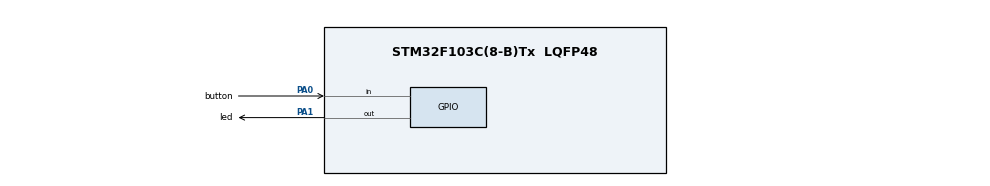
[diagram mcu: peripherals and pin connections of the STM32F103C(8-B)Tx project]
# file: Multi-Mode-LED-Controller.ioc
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Mcu.Family=STM32F1
Mcu.Name=STM32F103C(8-B)Tx
Mcu.Package=LQFP48
NVIC.PriorityGroup=NVIC_PRIORITYGROUP_4
PA0-WKUP.GPIO_Label=button
PA0-WKUP.GPIO_PuPd=GPIO_PULLUP
PA0-WKUP.Signal=GPIO_Input
PA1.GPIO_Label=led
PA1.Signal=GPIO_Output
ProjectManager.HeapSize=0x200
ProjectManager.StackSize=0x400
ProjectManager.TargetToolchain=STM32CubeIDE
RCC.APB1Freq_Value=8000000
RCC.APB2Freq_Value=8000000
board=custom

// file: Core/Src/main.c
/* USER CODE BEGIN Header */
/**
  ******************************************************************************
  * @file           : main.c
  * @brief          : Main program body
  ******************************************************************************
  * @attention
  *
  * Copyright (c) 2026 STMicroelectronics.
  * All rights reserved.
  *
  * This software is licensed under terms that can be found in the LICENSE file
  * in the root directory of this software component.
  * If no LICENSE file comes with this software, it is provided AS-IS.
  *
  ******************************************************************************
  */
/* USER CODE END Header */
#include "main.h"

void SystemClock_Config(void);
static void MX_GPIO_Init(void);

int main(void)
{

  /* MCU Configuration--------------------------------------------------------*/

  /* Reset of all peripherals, Initializes the Flash interface and the Systick. */
  HAL_Init();

  /* Configure the system clock */
  SystemClock_Config();

  /* Initialize all configured peripherals */
  MX_GPIO_Init();

  /* Infinite loop */
  /* USER CODE BEGIN WHILE */

  typedef enum
  {
      MODE_OFF,
      MODE_ON,
      MODE_BLINK_500MS,
      MODE_BLINK_100MS

  } LED_Mode;

  LED_Mode mode = MODE_OFF;

  uint32_t current_time;
  uint32_t previous_time = 0;
  uint32_t debounce_time = 0;

  uint8_t current_button = 0;
  uint8_t previous_button = 0;
  uint8_t led_state = 0;

  while (1)
  {
	  current_time = HAL_GetTick();
	  current_button = HAL_GPIO_ReadPin(GPIOA, GPIO_PIN_0);

	  if ((current_time - debounce_time) >= 30)
	  {
	      debounce_time = current_time;

	      if (current_button == GPIO_PIN_SET && previous_button == GPIO_PIN_RESET)
	      {
	          mode = (mode + 1) % 4;

	          previous_time = current_time;
	          led_state = 0;

	          if (mode == MODE_ON || mode == MODE_BLINK_500MS || mode == MODE_BLINK_100MS)
	          {
	              if (mode == MODE_ON)
	                  led_state = 1;
	              else
	                  led_state = 1;
	          }

	          HAL_GPIO_WritePin(GPIOA, GPIO_PIN_5, led_state ? GPIO_PIN_SET : GPIO_PIN_RESET);
	      }

	      previous_button = current_button;
	  }

	  switch(mode)
	  {
	  case MODE_OFF:
		  HAL_GPIO_WritePin(GPIOA, GPIO_PIN_1, GPIO_PIN_RESET);
		  break;

	  case MODE_ON:
		  HAL_GPIO_WritePin(GPIOA, GPIO_PIN_1, GPIO_PIN_SET);
		  break;

	  case MODE_BLINK_500MS:
		  if((current_time - previous_time) >= 500)
		  {
			  previous_time = current_time;
			  HAL_GPIO_TogglePin(GPIOA, GPIO_PIN_1);
		  }
		  break;

	  case MODE_BLINK_100MS:
		  if((current_time - previous_time) >= 100)
		  {
			  previous_time = current_time;
			  HAL_GPIO_TogglePin(GPIOA, GPIO_PIN_1);
		  }
		  break;

	  default:
		  break;
	  }
	  /* USER CODE END WHILE */

  }
}

void SystemClock_Config(void)
{
  RCC_OscInitTypeDef RCC_OscInitStruct = {0};
  RCC_ClkInitTypeDef RCC_ClkInitStruct = {0};

  /** Initializes the RCC Oscillators according to the specified parameters
  * in the RCC_OscInitTypeDef structure.
  */
  RCC_OscInitStruct.OscillatorType = RCC_OSCILLATORTYPE_HSI;
  RCC_OscInitStruct.HSIState = RCC_HSI_ON;
  RCC_OscInitStruct.HSICalibrationValue = RCC_HSICALIBRATION_DEFAULT;
  RCC_OscInitStruct.PLL.PLLState = RCC_PLL_NONE;
  if (HAL_RCC_OscConfig(&RCC_OscInitStruct) != HAL_OK)
  {
    Error_Handler();
  }

  /** Initializes the CPU, AHB and APB buses clocks
  */
  RCC_ClkInitStruct.ClockType = RCC_CLOCKTYPE_HCLK|RCC_CLOCKTYPE_SYSCLK
                              |RCC_CLOCKTYPE_PCLK1|RCC_CLOCKTYPE_PCLK2;
  RCC_ClkInitStruct.SYSCLKSource = RCC_SYSCLKSOURCE_HSI;
  RCC_ClkInitStruct.AHBCLKDivider = RCC_SYSCLK_DIV1;
  RCC_ClkInitStruct.APB1CLKDivider = RCC_HCLK_DIV1;
  RCC_ClkInitStruct.APB2CLKDivider = RCC_HCLK_DIV1;

  if (HAL_RCC_ClockConfig(&RCC_ClkInitStruct, FLASH_LATENCY_0) != HAL_OK)
  {
    Error_Handler();
  }
}

static void MX_GPIO_Init(void)
{
  GPIO_InitTypeDef GPIO_InitStruct = {0};

  /* GPIO Ports Clock Enable */
  __HAL_RCC_GPIOA_CLK_ENABLE();

  /*Configure GPIO pin Output Level */
  HAL_GPIO_WritePin(led_GPIO_Port, led_Pin, GPIO_PIN_RESET);

  /*Configure GPIO pin : button_Pin */
  GPIO_InitStruct.Pin = button_Pin;
  GPIO_InitStruct.Mode = GPIO_MODE_INPUT;
  GPIO_InitStruct.Pull = GPIO_PULLUP;
  HAL_GPIO_Init(button_GPIO_Port, &GPIO_InitStruct);

  /*Configure GPIO pin : led_Pin */
  GPIO_InitStruct.Pin = led_Pin;
  GPIO_InitStruct.Mode = GPIO_MODE_OUTPUT_PP;
  GPIO_InitStruct.Pull = GPIO_NOPULL;
  GPIO_InitStruct.Speed = GPIO_SPEED_FREQ_LOW;
  HAL_GPIO_Init(led_GPIO_Port, &GPIO_InitStruct);

}

void Error_Handler(void)
{
  __disable_irq();
  while (1)
  {
  }
}
